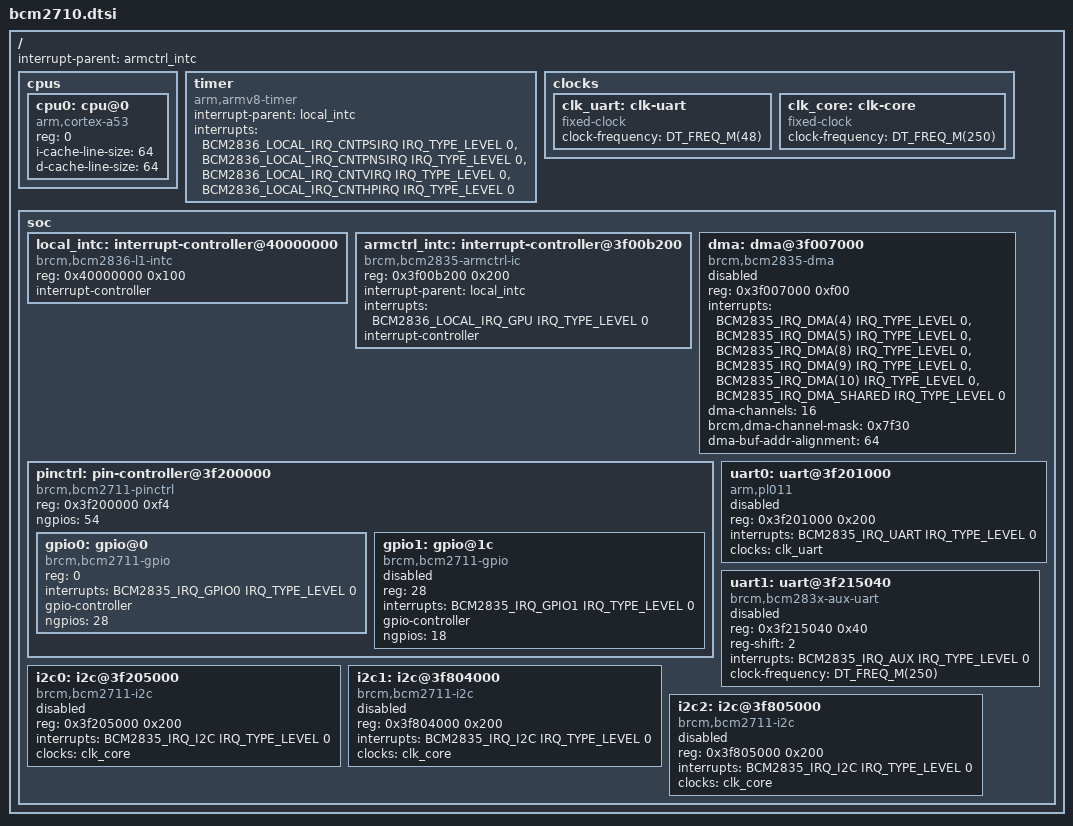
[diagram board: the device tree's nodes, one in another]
/*
 * Copyright (c) 2026 Jonathan Elliot Peace <jep@alphabetiq.com>
 *
 * SPDX-License-Identifier: Apache-2.0
 *
 * Broadcom BCM2710 SoC (Raspberry Pi 3 / Pi Zero 2 W).
 *
 * Interrupts are handled by the native BCM283x controller pair --
 * brcm,bcm2836-l1-intc (per-core timers, mailboxes, PMU and the GPU
 * cascade) and brcm,bcm2835-armctrl-ic (the peripheral aggregator) --
 * driven through the arm64 custom-interrupt-controller hooks in
 * soc/brcm/bcm2710/soc_irq.c.
 */

#include <mem.h>
#include <freq.h>

#include <arm64/armv8-a.dtsi>
#include <zephyr/dt-bindings/interrupt-controller/bcm2836-l1.h>
#include <zephyr/dt-bindings/interrupt-controller/bcm2835-armctrl.h>

/ {
	cpus {
		#address-cells = <1>;
		#size-cells = <0>;

		cpu0: cpu@0 {
			device_type = "cpu";
			compatible = "arm,cortex-a53";
			reg = <0>;
			i-cache-line-size = <64>;
			d-cache-line-size = <64>;
		};
	};

	interrupt-parent = <&armctrl_intc>;

	timer {
		compatible = "arm,armv8-timer";
		interrupt-parent = <&local_intc>;
		/* 0 = secure phys, 1 = nonsec phys, 2 = virtual, 3 = hyp phys */
		interrupts = <BCM2836_LOCAL_IRQ_CNTPSIRQ IRQ_TYPE_LEVEL 0>,
			     <BCM2836_LOCAL_IRQ_CNTPNSIRQ IRQ_TYPE_LEVEL 0>,
			     <BCM2836_LOCAL_IRQ_CNTVIRQ IRQ_TYPE_LEVEL 0>,
			     <BCM2836_LOCAL_IRQ_CNTHPIRQ IRQ_TYPE_LEVEL 0>;
	};

	clocks {
		clk_uart: clk-uart {
			compatible = "fixed-clock";
			clock-frequency = <DT_FREQ_M(48)>;
			#clock-cells = <0>;
		};

		/* VPU core clock; tracks the firmware-side core_freq. */
		clk_core: clk-core {
			compatible = "fixed-clock";
			clock-frequency = <DT_FREQ_M(250)>;
			#clock-cells = <0>;
		};
	};

	soc {
		local_intc: interrupt-controller@40000000 {
			compatible = "brcm,bcm2836-l1-intc";
			reg = <0x40000000 0x100>;
			interrupt-controller;
			#interrupt-cells = <3>;
			status = "okay";
		};

		armctrl_intc: interrupt-controller@3f00b200 {
			compatible = "brcm,bcm2835-armctrl-ic";
			reg = <0x3f00b200 0x200>;
			interrupt-parent = <&local_intc>;
			interrupts = <BCM2836_LOCAL_IRQ_GPU IRQ_TYPE_LEVEL 0>;
			interrupt-controller;
			#interrupt-cells = <3>;
			status = "okay";
		};

		/*
		 * DMA controller -- a control-block (linked-list
		 * descriptor) engine. Peripherals such as I2S and SPI can
		 * pace transfers off it via DREQ. Default disabled;
		 * boards / test overlays opt in.
		 *
		 * brcm,dma-channel-mask = 0x7f30 keeps channels 4,5,8..14
		 * and excludes the VideoCore-firmware-reserved and
		 * special-function channels (0,1,2,3,6,7). The interrupts
		 * list covers exactly those mask channels: 4,5,8,9,10 have
		 * dedicated lines, 11..14 share one.
		 */
		dma: dma@3f007000 {
			compatible = "brcm,bcm2835-dma";
			reg = <0x3f007000 0xf00>;
			interrupts = <BCM2835_IRQ_DMA(4)  IRQ_TYPE_LEVEL 0>,
				     <BCM2835_IRQ_DMA(5)  IRQ_TYPE_LEVEL 0>,
				     <BCM2835_IRQ_DMA(8)  IRQ_TYPE_LEVEL 0>,
				     <BCM2835_IRQ_DMA(9)  IRQ_TYPE_LEVEL 0>,
				     <BCM2835_IRQ_DMA(10) IRQ_TYPE_LEVEL 0>,
				     <BCM2835_IRQ_DMA_SHARED IRQ_TYPE_LEVEL 0>;
			#dma-cells = <1>;
			dma-channels = <16>;
			brcm,dma-channel-mask = <0x7f30>;
			dma-buf-addr-alignment = <64>;
			status = "disabled";
		};

		pinctrl: pin-controller@3f200000 {
			compatible = "brcm,bcm2711-pinctrl";
			reg = <0x3f200000 0xf4>;
			ngpios = <54>;
			#address-cells = <1>;
			#size-cells = <0>;

			gpio0: gpio@0 {
				compatible = "brcm,bcm2711-gpio";
				reg = <0>;
				interrupts = <BCM2835_IRQ_GPIO0 IRQ_TYPE_LEVEL 0>;
				gpio-controller;
				#gpio-cells = <2>;
				ngpios = <28>;
				status = "okay";
			};

			gpio1: gpio@1c {
				compatible = "brcm,bcm2711-gpio";
				reg = <28>;
				interrupts = <BCM2835_IRQ_GPIO1 IRQ_TYPE_LEVEL 0>;
				gpio-controller;
				#gpio-cells = <2>;
				ngpios = <18>;
				status = "disabled";
			};
		};

		uart0: uart@3f201000 {
			compatible = "arm,pl011";
			reg = <0x3f201000 0x200>;
			interrupts = <BCM2835_IRQ_UART IRQ_TYPE_LEVEL 0>;
			interrupt-names = "uart0";
			clocks = <&clk_uart>;
			status = "disabled";
		};

		uart1: uart@3f215040 {
			compatible = "brcm,bcm283x-aux-uart", "ns16550";
			reg = <0x3f215040 0x40>;
			reg-shift = <2>;
			interrupts = <BCM2835_IRQ_AUX IRQ_TYPE_LEVEL 0>;
			clock-frequency = <DT_FREQ_M(250)>;
			status = "disabled";
		};

		/*
		 * The three BSC masters share BCM2835_IRQ_I2C, so enabling
		 * more than one at a time trips a build-time IRQ_CONNECT
		 * duplicate.
		 */
		i2c0: i2c@3f205000 {
			compatible = "brcm,bcm2711-i2c";
			reg = <0x3f205000 0x200>;
			interrupts = <BCM2835_IRQ_I2C IRQ_TYPE_LEVEL 0>;
			clocks = <&clk_core>;
			#address-cells = <1>;
			#size-cells = <0>;
			status = "disabled";
		};

		i2c1: i2c@3f804000 {
			compatible = "brcm,bcm2711-i2c";
			reg = <0x3f804000 0x200>;
			interrupts = <BCM2835_IRQ_I2C IRQ_TYPE_LEVEL 0>;
			clocks = <&clk_core>;
			#address-cells = <1>;
			#size-cells = <0>;
			status = "disabled";
		};

		i2c2: i2c@3f805000 {
			compatible = "brcm,bcm2711-i2c";
			reg = <0x3f805000 0x200>;
			interrupts = <BCM2835_IRQ_I2C IRQ_TYPE_LEVEL 0>;
			clocks = <&clk_core>;
			#address-cells = <1>;
			#size-cells = <0>;
			status = "disabled";
		};
	};
};
